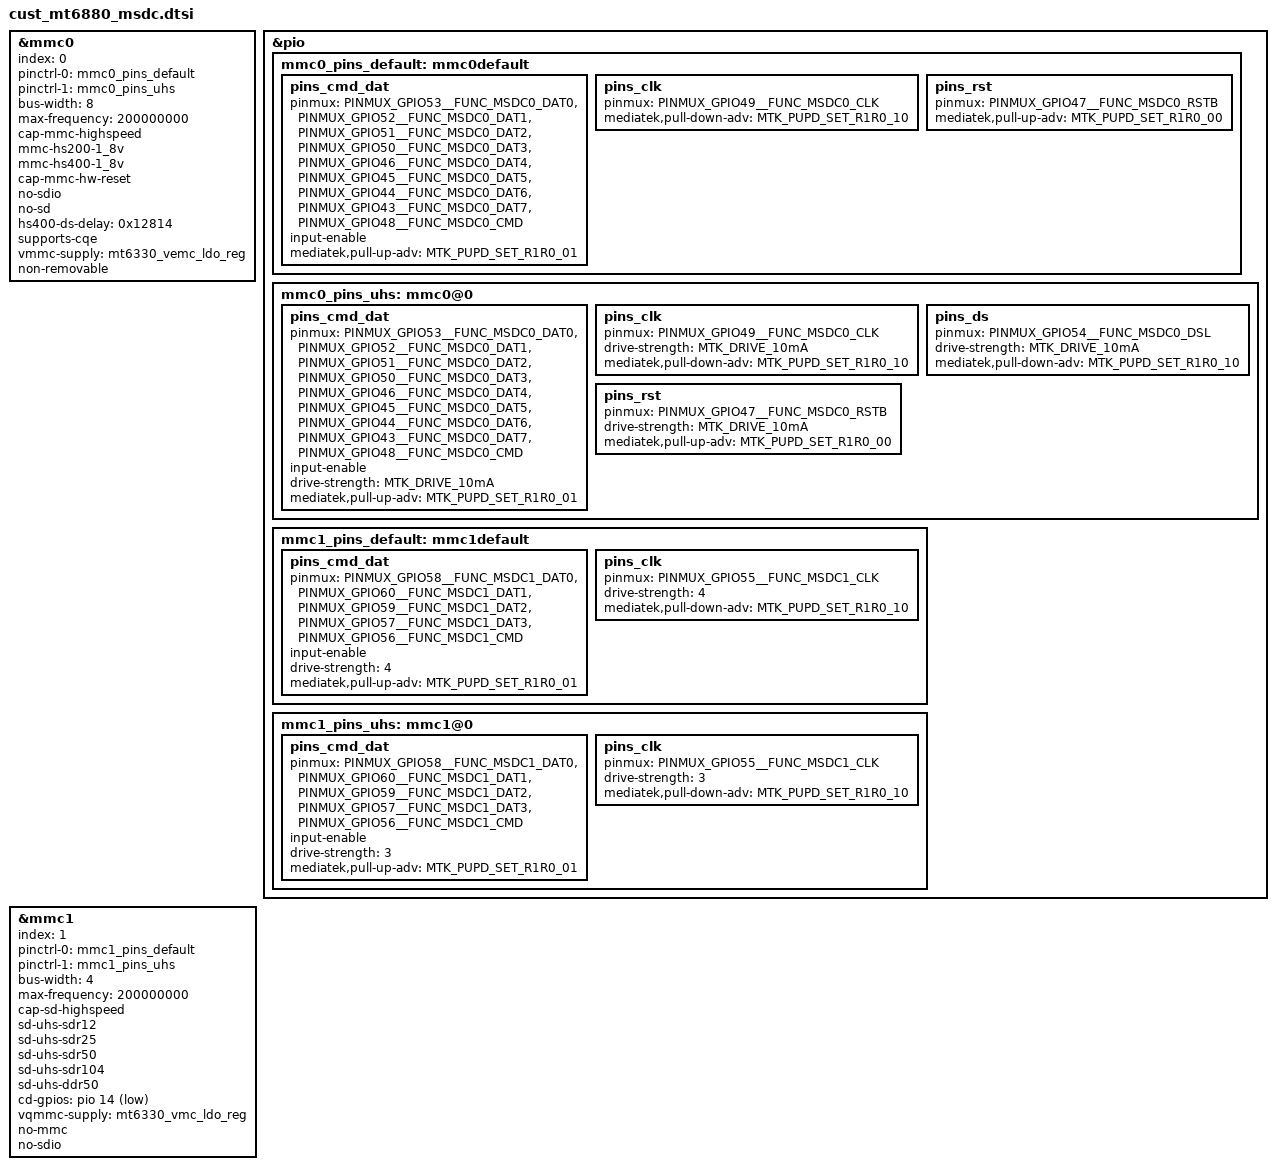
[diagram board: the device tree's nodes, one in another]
// SPDX-License-Identifier: GPL-2.0
/*
 * Copyright (c) 2019 MediaTek Inc.
 */
/********************************************
 * MT6880 MSDC DTSI File
 ********************************************/
#include <dt-bindings/gpio/gpio.h>

&mmc0 {
	index = <0>;
	status = "okay";
	pinctrl-names = "default", "state_uhs";
	pinctrl-0 = <&mmc0_pins_default>;
	pinctrl-1 = <&mmc0_pins_uhs>;
	bus-width = <8>;
	max-frequency = <200000000>;
	cap-mmc-highspeed;
	mmc-hs200-1_8v;
	mmc-hs400-1_8v;
	cap-mmc-hw-reset;
	no-sdio;
	no-sd;
	hs400-ds-delay = <0x12814>;
	supports-cqe;
	vmmc-supply = <&mt6330_vemc_ldo_reg>;
	non-removable;
};

&pio {
	mmc0_pins_default: mmc0default {
		pins_cmd_dat {
			pinmux = <PINMUX_GPIO53__FUNC_MSDC0_DAT0>,
				 <PINMUX_GPIO52__FUNC_MSDC0_DAT1>,
				 <PINMUX_GPIO51__FUNC_MSDC0_DAT2>,
				 <PINMUX_GPIO50__FUNC_MSDC0_DAT3>,
				 <PINMUX_GPIO46__FUNC_MSDC0_DAT4>,
				 <PINMUX_GPIO45__FUNC_MSDC0_DAT5>,
				 <PINMUX_GPIO44__FUNC_MSDC0_DAT6>,
				 <PINMUX_GPIO43__FUNC_MSDC0_DAT7>,
				 <PINMUX_GPIO48__FUNC_MSDC0_CMD>;
			input-enable;
			mediatek,pull-up-adv = <MTK_PUPD_SET_R1R0_01>;
		};
		pins_clk {
			pinmux = <PINMUX_GPIO49__FUNC_MSDC0_CLK>;
			mediatek,pull-down-adv = <MTK_PUPD_SET_R1R0_10>;
		};
		pins_rst {
			pinmux = <PINMUX_GPIO47__FUNC_MSDC0_RSTB>;
			mediatek,pull-up-adv = <MTK_PUPD_SET_R1R0_00>;
		};
	};
	mmc0_pins_uhs: mmc0@0{
		pins_cmd_dat {
			pinmux = <PINMUX_GPIO53__FUNC_MSDC0_DAT0>,
				 <PINMUX_GPIO52__FUNC_MSDC0_DAT1>,
				 <PINMUX_GPIO51__FUNC_MSDC0_DAT2>,
				 <PINMUX_GPIO50__FUNC_MSDC0_DAT3>,
				 <PINMUX_GPIO46__FUNC_MSDC0_DAT4>,
				 <PINMUX_GPIO45__FUNC_MSDC0_DAT5>,
				 <PINMUX_GPIO44__FUNC_MSDC0_DAT6>,
				 <PINMUX_GPIO43__FUNC_MSDC0_DAT7>,
				 <PINMUX_GPIO48__FUNC_MSDC0_CMD>;
			input-enable;
			drive-strength = <MTK_DRIVE_10mA>;
			mediatek,pull-up-adv = <MTK_PUPD_SET_R1R0_01>;
		};
		pins_clk {
			pinmux = <PINMUX_GPIO49__FUNC_MSDC0_CLK>;
			drive-strength = <MTK_DRIVE_10mA>;
			mediatek,pull-down-adv = <MTK_PUPD_SET_R1R0_10>;
		};
		pins_ds {
			pinmux = <PINMUX_GPIO54__FUNC_MSDC0_DSL>;
			drive-strength = <MTK_DRIVE_10mA>;
			mediatek,pull-down-adv = <MTK_PUPD_SET_R1R0_10>;
		};
		pins_rst {
			pinmux = <PINMUX_GPIO47__FUNC_MSDC0_RSTB>;
			drive-strength = <MTK_DRIVE_10mA>;
			mediatek,pull-up-adv = <MTK_PUPD_SET_R1R0_00>;
		};
	};
};

&mmc1 {
	index = <1>;
	status = "okay";
	pinctrl-names = "default", "state_uhs";
	pinctrl-0 = <&mmc1_pins_default>;
	pinctrl-1 = <&mmc1_pins_uhs>;
//	pinctrl-2 = <&mmc1_a_pins_default>;
//	pinctrl-3 = <&mmc1_a_pins_uhs>;
	bus-width = <4>;
	max-frequency = <200000000>;
	cap-sd-highspeed;
	sd-uhs-sdr12;
	sd-uhs-sdr25;
	sd-uhs-sdr50;
	sd-uhs-sdr104;
	sd-uhs-ddr50;
	cd-gpios = <&pio 14 GPIO_ACTIVE_LOW>;
	vqmmc-supply = <&mt6330_vmc_ldo_reg>;
	no-mmc;
	no-sdio;
};

&pio {
#if 1
	mmc1_pins_default: mmc1default {
		pins_cmd_dat {
			pinmux = <PINMUX_GPIO58__FUNC_MSDC1_DAT0>,
				<PINMUX_GPIO60__FUNC_MSDC1_DAT1>,
				<PINMUX_GPIO59__FUNC_MSDC1_DAT2>,
				<PINMUX_GPIO57__FUNC_MSDC1_DAT3>,
				<PINMUX_GPIO56__FUNC_MSDC1_CMD>;
			input-enable;
			drive-strength = <4>;
			mediatek,pull-up-adv = <MTK_PUPD_SET_R1R0_01>;
		};

		pins_clk {
			pinmux = <PINMUX_GPIO55__FUNC_MSDC1_CLK>;
			drive-strength = <4>;
			mediatek,pull-down-adv = <MTK_PUPD_SET_R1R0_10>;
		};

//		pins_insert {
//			pinmux = <PINMUX_GPIO14__FUNC_GPIO14>;
//			bias-pull-up;
//		};
	};

	mmc1_pins_uhs: mmc1@0{
		pins_cmd_dat {
			pinmux = <PINMUX_GPIO58__FUNC_MSDC1_DAT0>,
				<PINMUX_GPIO60__FUNC_MSDC1_DAT1>,
				<PINMUX_GPIO59__FUNC_MSDC1_DAT2>,
				<PINMUX_GPIO57__FUNC_MSDC1_DAT3>,
				<PINMUX_GPIO56__FUNC_MSDC1_CMD>;
			input-enable;
			drive-strength = <3>;
			mediatek,pull-up-adv = <MTK_PUPD_SET_R1R0_01>;
		};

		pins_clk {
			pinmux = <PINMUX_GPIO55__FUNC_MSDC1_CLK>;
			drive-strength = <3>;
			mediatek,pull-down-adv = <MTK_PUPD_SET_R1R0_10>;
		};
	};
#endif
#if 0
	mmc1_pins_default: mmc1default {
		pins_cmd_dat {
			pinmux = <PINMUX_GPIO29__FUNC_MSDC1_DAT0_A>,
				<PINMUX_GPIO31__FUNC_MSDC1_DAT1_A>,
				<PINMUX_GPIO30__FUNC_MSDC1_DAT2_A>,
				<PINMUX_GPIO28__FUNC_MSDC1_DAT3_A>,
				<PINMUX_GPIO27__FUNC_MSDC1_CMD_A>;
			input-enable;
			drive-strength = <4>;
			mediatek,pull-up-adv = <MTK_PUPD_SET_R1R0_01>;
		};

		pins_clk {
			pinmux = <PINMUX_GPIO26__FUNC_MSDC1_CLK_A>;
			drive-strength = <4>;
			mediatek,pull-down-adv = <MTK_PUPD_SET_R1R0_10>;
		};

//		pins_insert {
//			pinmux = <PINMUX_GPIO14__FUNC_GPIO14>;
//			bias-pull-up;
//		};
	};

	mmc1_pins_uhs: mmc1@0{
		pins_cmd_dat {
			pinmux = <PINMUX_GPIO29__FUNC_MSDC1_DAT0_A>,
				<PINMUX_GPIO31__FUNC_MSDC1_DAT1_A>,
				<PINMUX_GPIO30__FUNC_MSDC1_DAT2_A>,
				<PINMUX_GPIO28__FUNC_MSDC1_DAT3_A>,
				<PINMUX_GPIO27__FUNC_MSDC1_CMD_A>;
			input-enable;
			drive-strength = <3>;
			mediatek,pull-up-adv = <MTK_PUPD_SET_R1R0_01>;
		};

		pins_clk {
			pinmux = <PINMUX_GPIO26__FUNC_MSDC1_CLK_A>;
			drive-strength = <3>;
			mediatek,pull-down-adv = <MTK_PUPD_SET_R1R0_10>;
		};
	};
#endif
};
